# NUC029AE_v1 register map
File version: 1.0
NUC029AE_v1 SVD file
Registers are 32-bit, read-write, reset 0x0 unless marked. A register's access mark holds for its fields unless they carry their own. Offsets are from the block's base; lines under a group give offsets from that group; [hi:lo] are bit positions; {n}, {i} and the like mark numbered series; 'fields as' and 'values as' point back to an identical list; <NAME> marks a mode.

## Memory map
0x40004000 WDT size 0x4 — WDT Register Map
0x40010000 TMR blocks up to offset 0x3C — TMR Register Map
0x40020000 I2C blocks up to offset 0x44 — I2C Register Map
0x40030000 SPI blocks up to offset 0x48 — SPI Register Map
0x40040000 PWM blocks up to offset 0x88 — PWM Register Map
0x40050000 UART size 0x34 — UART Register Map
0x400D0000 ACMP size 0x10 — ACMP Register Map
0x400E0000 ADC blocks up to offset 0x4C — ADC Register Map
0x50000000 GCR blocks up to offset 0x104 — GCR Register Map
0x50000200 CLK blocks up to offset 0x28 — CLK Register Map
0x50000300 INT size 0x88 — INT Register Map
0x50004000 GP blocks up to offset 0x2B8 — GPIO Register Map
0x5000C000 FMC blocks up to offset 0x44 — FMC Register Map
0xE000E000 SCS blocks up to offset 0xD24 — SCS Register Map

## INT — INT Register Map
Base 0x50000300
{0x0+4i} IRQ{i}_SRC ro reset not defined (i=0..31) — IRQ{i} (BOD) Interrupt Source Identity
  [2:0] INT_SRC — Interrupt Source. Define the interrupt sources for interrupt event.
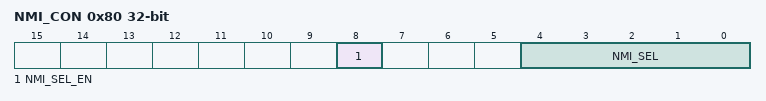
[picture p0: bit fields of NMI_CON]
0x80 NMI_CON — NMI Source Interrupt Select Control Register
  [8] NMI_SEL_EN — NMI Interrupt Enable Control (Write Protect). Note: This bit is the protected bit, and programming it needs to write 0x59, 0x16, and 0x88 to address 0x5000_0100 to disable register protection. Refer to the register REGWRPROT at address GCR_BA+0x100.
    0=NMI interrupt Disabled; 1=NMI interrupt Enabled
  [4:0] NMI_SEL — NMI Interrupt Source Selection. The NMI interrupt to Cortex-M0 can be selected from one of the peripheral interrupt by setting NMI_SEL.
0x84 MCU_IRQ — MCU IRQ Number Identity Register
  [31:0] MCU_IRQ — MCU IRQ Source. The MCU_IRQ collects all the interrupts from the peripherals and generates the synchronous interrupt to Cortex-M0 core. There are two modes to generate interrupt to Cortex-M0 - the normal mode and test mode. The MCU_IRQ collects all interrupts from each peripheral and synchronizes them then interrupts the Cortex-M0. When the MCU_IRQ[n] is 0, setting MCU_IRQ[n] to 1 will generate an interrupt to Cortex-M0 NVIC[n]. When the MCU_IRQ[n] is 1 (mean an interrupt is assert), setting 1 to the MCU_bit[n] will clear the interrupt and setting MCU_IRQ[n] 0 has no effect.

## FMC — FMC Register Map
Base 0x5000C000
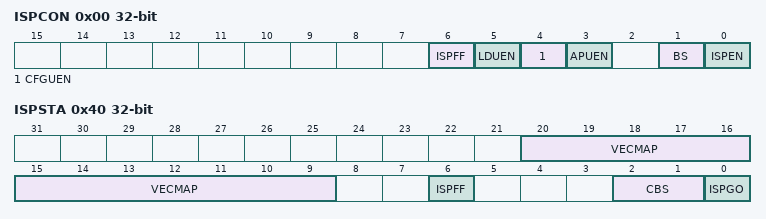
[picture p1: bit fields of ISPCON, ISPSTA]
0x00 ISPCON — ISP Control Register
  [6] ISPFF — ISP Fail Flag (Write Protect). This bit is set by hardware when a triggered ISP meets any of the following conditions: (3) User Configuration is erased/programmed when CFGUEN is 0. (4) Destination address is illegal, such as over an available range. Note: Write 1 to clear this bit to 0.
  [5] LDUEN — LDROM Update Enable Control (Write Protect)
    0=LDROM cannot be updated; 1=LDROM can be updated when the MCU runs in APROM
  [4] CFGUEN — CONFIG Update Enable Control (Write Protect). Writing this bit to 1 enables software to update CONFIG value by ISP register control procedure regardless of program code is running in APROM or LDROM.
    0=ISP update User Configuration Disabled; 1=ISP update User Configuration Enabled
  [3] APUEN — APROM Update Enable Control (Write Protect)
    0=APROM cannot be updated when chip runs in APROM; 1=APROM can be updated when chip runs in APROM
  [1] BS — Boot Select (Write Protect). Set/clear this bit to select next booting from LDROM/APROM, respectively. This bit also functions as chip booting status flag, which can be used to check where chip booted from. This bit is initiated with the inversed value of CBS in CONFIG0 after any reset is happened except CPU reset (RSTS_CPU is 1) or system reset (RSTS_SYS) is happened.
    0=Boot from APROM; 1=Boot from LDROM
  [0] ISPEN — ISP Enable Control (Write Protect). Set this bit to enable ISP function.
    0=ISP function Disabled; 1=ISP function Enabled
0x04 ISPADR — ISP Address Register
  [31:0] ISPADR — ISP Address. The NuMicro NUC029 series supports word program only. ISPADR[1:0] must be kept 00 for ISP operation.
0x08 ISPDAT — ISP Data Register
  [31:0] ISPDAT — ISP Data. Write data to this register before ISP program operation. Read data from this register after ISP read operation.
0x0C ISPCMD — ISP Command Register
  [5:0] ISPCMD — ISP Command. ISP commands are shown below:
    0=Read; 4=Read Unique ID; 11=Read Company ID (0xDA); 33=Program; 34=Page Erase; 46=Set Vector Page Re-Map
0x10 ISPTRG — ISP Trigger Register
  [0] ISPGO — ISP Start Trigger (Write Protect). Write 1 to start ISP operation and this bit will be cleared to 0 by hardware automatically when ISP operation is finished.
    0=ISP operation is finished; 1=ISP operation is progressed
0x14 DFBA ro reset 0x3800 — Data Flash Start Address
  [31:0] DFBA — Data Flash Base Address. This register indicates data flash start address. It is a read only register. The data flash start address is defined by user. Since on chip flash erase unit is 512 bytes, it is mandatory to keep bit 8-0 as 0.
0x40 ISPSTA — ISP Status Register
  [20:9] VECMAP ro — Vector Page Mapping Address (Read Only). The current flash address space 0x0000_0000~0x0000_01FF is mapping to address {VECMAP[11:0], 9'h000} ~ {VECMAP[11:0], 9'h1FF}.
  [6] ISPFF — ISP Fail Flag (Write Protect). This bit is set by hardware when a triggered ISP meets any of the following conditions: (3) User Configuration is erased/programmed when CFGUEN is 0. (4) Destination address is illegal, such as over an available range. Write 1 to clear. Note: This bit functions the same as ISPCON bit 6.
  [2:1] CBS ro — Config Boot Selection (Read only). This is a mirror of CBS in CONFIG0.
  [0] ISPGO ro — ISP Start Trigger (Read only). Write 1 to start ISP operation and this bit will be cleared to 0 by hardware automatically when ISP operation is finished. Note: This bit is the same with ISPTRG bit 0.
    0=ISP operation is finished; 1=ISP operation is progressed
